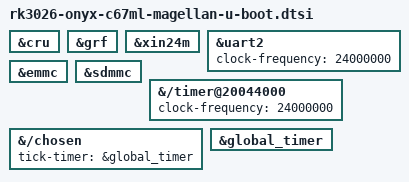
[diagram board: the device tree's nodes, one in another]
// SPDX-License-Identifier: (GPL-2.0+ OR MIT)
/*
 * U-Boot specific additions for the ONYX BOOX C67ML Magellan.
 *
 * Copyright (c) 2024, Mario Rugiero
 *
 * Pulls in the shared Rockchip binman image description and marks the
 * boot-essential nodes for the pre-relocation (SPL) phase.  The board DTS
 * already carries inline u-boot,dm-pre-reloc on uart2/emmc/sdmmc/i2c0; this
 * overlay adds the SoC infrastructure (cru, grf, oscillator) the early DM
 * needs before relocation.
 */

#include "rockchip-u-boot.dtsi"

&cru {
	bootph-all;
};

&grf {
	bootph-all;
};

&xin24m {
	bootph-all;
};

&uart2 {
	bootph-all;
	clock-frequency = <24000000>;
};

&emmc {
	bootph-all;
};

&sdmmc {
	bootph-all;
	/* fifo-mode is set in the canonical board dts (dts/), not here --
	 * it applies to the kernel build too, so it belongs in one place.
	 * See that file's &sdmmc node for the measurement it's based on. */
};

/*
 * timer_pre_probe() asks the CRU for PCLK_TIMER0 first and
 * rk3026_clk_get_rate() has no case for it, so without this property
 * clock_rate stays 0 and timer_post_probe() rejects the device.  A dead
 * get_timer() then makes wait_for_bit_le32() spin forever instead of timing
 * out (include/wait_bit.h:45), which hangs acm_stdio_start() -- the LED
 * rhythms still run (spin loops) but USB never enumerates.
 *
 * PROVEN on hardware 2026-07-29 (card 78, 4:1 match).  Regressed 2026-07-29
 * by f513e0e, which copied the canonical dtsi over this tree's; kept here
 * rather than in dts/ because it is a U-Boot driver workaround and because
 * this overlay is the one file no canonical sync overwrites.
 *
 * 24 MHz is device-measured (timer1 sampled 30 s apart: 24,000,665 Hz).
 *
 * ⚠️ DO NOT remove this by teaching rk3026_clk_get_rate() about PCLK_TIMER0.
 * An earlier revision of this comment suggested exactly that, which is a trap:
 * timer_pre_probe() takes clk index 0 as the COUNTING rate and returns at
 * timer-uclass.c:70 before it ever reads clock-frequency, so the timebase would
 * silently run at the ~66 MHz APB rate instead of xin24m's 24 MHz. Retiring this
 * property needs timer_pre_probe() fixed to prefer the "timer"-named clock --
 * an upstream change. See docs/PORT-FIXES.md §3b.
 */
&{/timer@20044000} {
	clock-frequency = <24000000>;
};

/*
 * Make the A9 MPCore global timer the DM tick timer.
 *
 * dm_timer_init() looks for /chosen/tick-timer and gives up without it -- which
 * is why an earlier note in docs/BLOCKERS.md said enabling ARM_GLOBAL_TIMER
 * "would hang the console": the symbol alone, with no chosen node, leaves the
 * timebase unresolved. Supplying the node is the missing half.
 *
 * Written as a reference (tick-timer = &node), the form every in-tree user
 * takes -- see am335x-bone-common.dtsi -- not as a path string.
 *
 * Its rate comes from clocks = <&cru CORE_PERI> in rk3026.dtsi, which is now
 * both implemented in the driver and MEASURED correct: 100.0139 MHz against
 * APLL/6 = 100.000 MHz (docs/HARDWARE-CONSTANTS.md).
 *
 * Two reasons to prefer it over timer0: it is a genuine 64-bit counter, and
 * arm_global_timer.c already reads the halves with a high/low/high retry, so it
 * is structurally free of the torn read that timer0 needed a fix for.
 */
&{/chosen} {
	tick-timer = &global_timer;
};

&global_timer {
	bootph-all;

	/*
	 * Canonical DISABLES this node, correctly, for Linux: arm_global_timer's
	 * rate follows the CPU, so its clocksource and sched_clock go wrong the
	 * moment cpufreq moves armclk.
	 *
	 * U-Boot is the genuine exception and this is the ONLY legitimate DTS
	 * difference between the two builds: no cpufreq, APLL set once, and the
	 * U-Boot clk driver does implement CORE_PERI (measured 100.0139 MHz
	 * against APLL/6 = 100.000 MHz).
	 *
	 * It lives here rather than in dts/ because this overlay is the one file
	 * propagation never overwrites -- the same reason the timer0
	 * clock-frequency workaround above sits here after f513e0e lost it.
	 *
	 * ⚠️ Without this, the tick-timer reference above resolves to a disabled
	 * node, get_timer() is dead, and wait_for_bit_le32() spins forever
	 * instead of timing out (include/wait_bit.h:45) -- which presents as
	 * U-Boot hanging with no console, not as an error.
	 */
	status = "okay";
};
